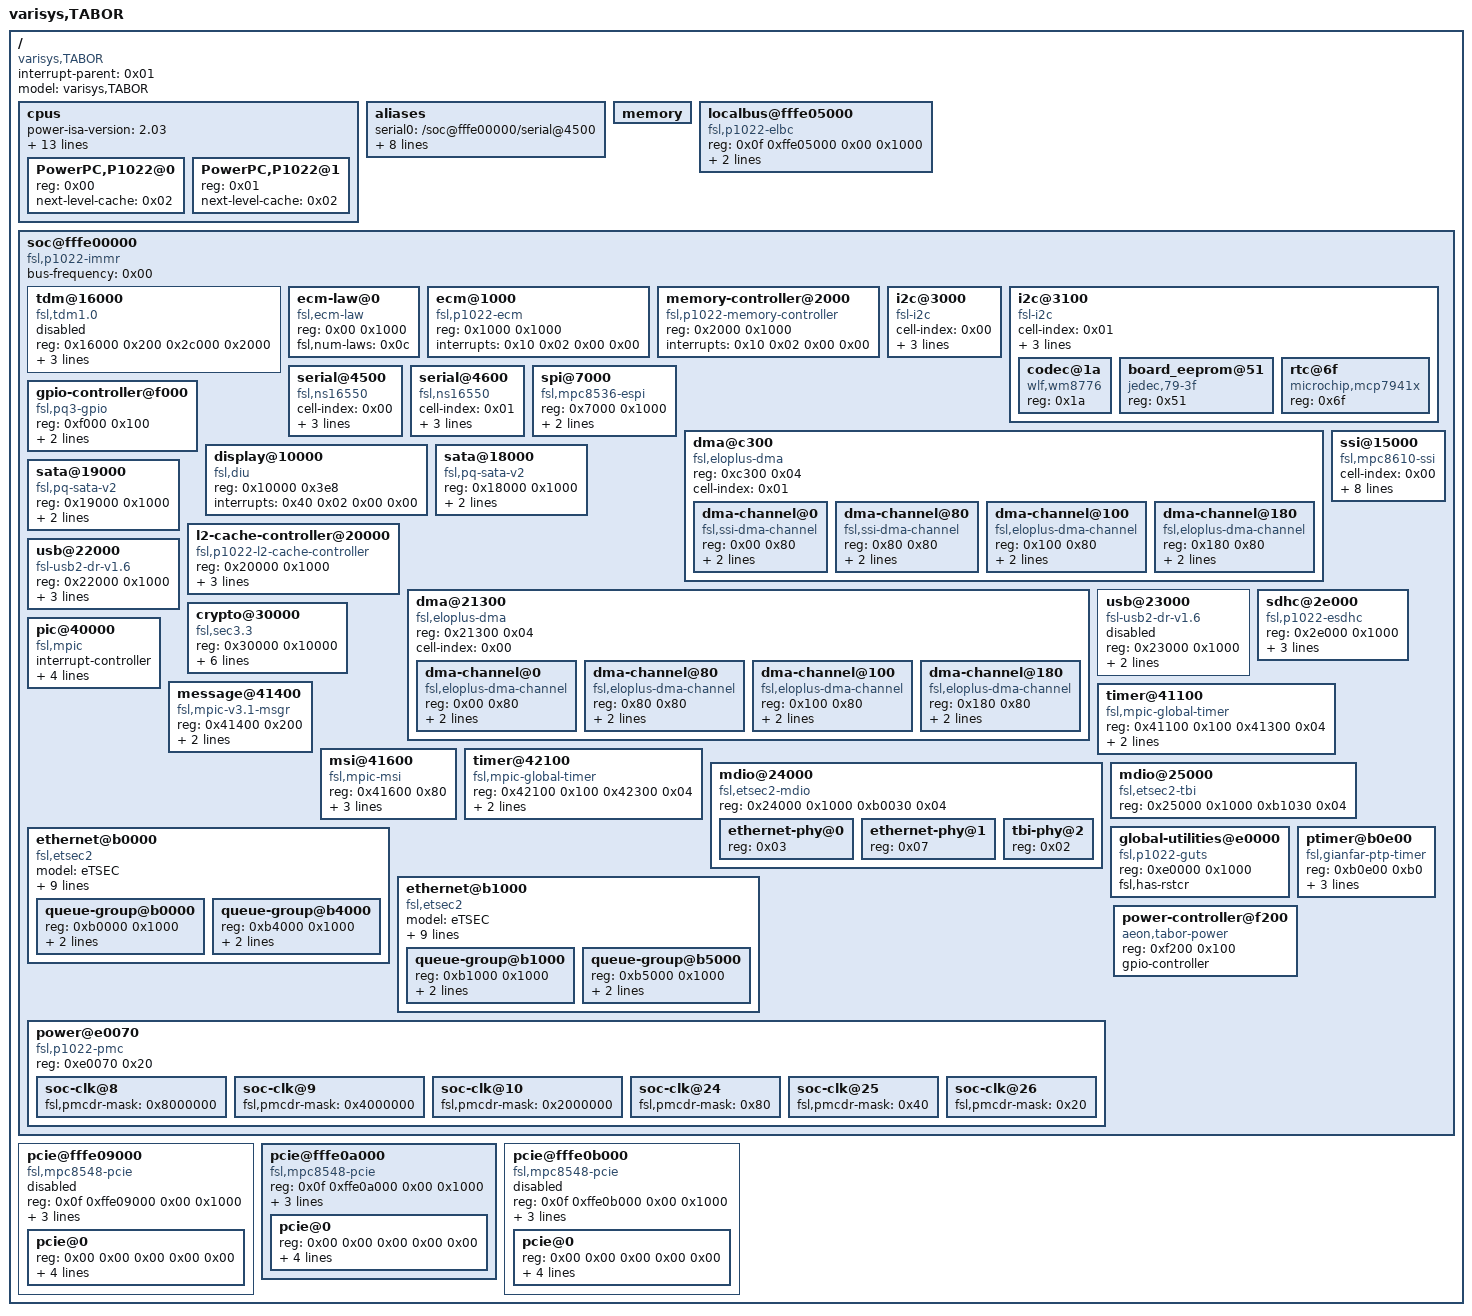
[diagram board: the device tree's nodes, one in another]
/dts-v1/;

/ {
	compatible = "varisys,TABOR";
	#address-cells = <0x02>;
	#size-cells = <0x02>;
	interrupt-parent = <0x01>;
	model = "varisys,TABOR";

	cpus {
		power-isa-version = "2.03";
		power-isa-b;
		power-isa-e;
		power-isa-atb;
		power-isa-cs;
		power-isa-e.le;
		power-isa-e.pm;
		power-isa-ecl;
		power-isa-mmc;
		power-isa-sp;
		power-isa-sp.fd;
		power-isa-sp.fs;
		power-isa-sp.fv;
		mmu-type = "power-embedded";
		#address-cells = <0x01>;
		#size-cells = <0x00>;

		PowerPC,P1022@0 {
			device_type = "cpu";
			reg = <0x00>;
			next-level-cache = <0x02>;
		};

		PowerPC,P1022@1 {
			device_type = "cpu";
			reg = <0x01>;
			next-level-cache = <0x02>;
		};
	};

	aliases {
		serial0 = "/soc@fffe00000/serial@4500";
		serial1 = "/soc@fffe00000/serial@4600";
		ethernet0 = "/soc@fffe00000/ethernet@b0000";
		ethernet1 = "/soc@fffe00000/ethernet@b1000";
		pci0 = "/pcie@fffe09000";
		pci1 = "/pcie@fffe0a000";
		pci2 = "/pcie@fffe0b000";
		vga = "/soc@fffe00000/display@10000";
		display = "/soc@fffe00000/display@10000";
	};

	memory {
		device_type = "memory";
	};

	localbus@fffe05000 {
		ranges = <0x00 0x00 0x0f 0xe8000000 0x8000000 0x01 0x00 0x0f 0xe0000000 0x8000000 0x02 0x00 0x0f 0xff800000 0x40000 0x03 0x00 0x0f 0xffdf0000 0x8000>;
		reg = <0x0f 0xffe05000 0x00 0x1000>;
		#address-cells = <0x02>;
		#size-cells = <0x01>;
		compatible = "fsl,p1022-elbc", "fsl,elbc";
		interrupts = <0x13 0x02 0x00 0x00 0x10 0x02 0x00 0x00>;
	};

	soc@fffe00000 {
		ranges = <0x00 0x0f 0xffe00000 0x100000>;
		#address-cells = <0x01>;
		#size-cells = <0x01>;
		device_type = "soc";
		compatible = "fsl,p1022-immr", "simple-bus";
		bus-frequency = <0x00>;

		tdm@16000 {
			status = "disabled";
			compatible = "fsl,tdm1.0";
			reg = <0x16000 0x200 0x2c000 0x2000>;
			clock-frequency = <0x00>;
			interrupts = <0x3e 0x08 0x00 0x00>;
			fsl,max-time-slots = <0x80>;
		};

		ecm-law@0 {
			compatible = "fsl,ecm-law";
			reg = <0x00 0x1000>;
			fsl,num-laws = <0x0c>;
		};

		ecm@1000 {
			compatible = "fsl,p1022-ecm", "fsl,ecm";
			reg = <0x1000 0x1000>;
			interrupts = <0x10 0x02 0x00 0x00>;
		};

		memory-controller@2000 {
			compatible = "fsl,p1022-memory-controller";
			reg = <0x2000 0x1000>;
			interrupts = <0x10 0x02 0x00 0x00>;
		};

		i2c@3000 {
			#address-cells = <0x01>;
			#size-cells = <0x00>;
			cell-index = <0x00>;
			compatible = "fsl-i2c";
			reg = <0x3000 0x100>;
			interrupts = <0x2b 0x02 0x00 0x00>;
			dfsrr;
		};

		i2c@3100 {
			#address-cells = <0x01>;
			#size-cells = <0x00>;
			cell-index = <0x01>;
			compatible = "fsl-i2c";
			reg = <0x3100 0x100>;
			interrupts = <0x2b 0x02 0x00 0x00>;
			dfsrr;

			codec@1a {
				compatible = "wlf,wm8776";
				reg = <0x1a>;
				linux,phandle = <0x05>;
				phandle = <0x05>;
			};

			board_eeprom@51 {
				compatible = "jedec,79-3f";
				reg = <0x51>;
			};

			rtc@6f {
				compatible = "microchip,mcp7941x";
				reg = <0x6f>;
			};
		};

		serial@4500 {
			cell-index = <0x00>;
			device_type = "serial";
			compatible = "fsl,ns16550", "ns16550";
			reg = <0x4500 0x100>;
			clock-frequency = <0x00>;
			interrupts = <0x2a 0x02 0x00 0x00>;
		};

		serial@4600 {
			cell-index = <0x01>;
			device_type = "serial";
			compatible = "fsl,ns16550", "ns16550";
			reg = <0x4600 0x100>;
			clock-frequency = <0x00>;
			interrupts = <0x2a 0x02 0x00 0x00>;
		};

		spi@7000 {
			#address-cells = <0x01>;
			#size-cells = <0x00>;
			compatible = "fsl,mpc8536-espi";
			reg = <0x7000 0x1000>;
			interrupts = <0x3b 0x02 0x00 0x00>;
			fsl,espi-num-chipselects = <0x04>;
		};

		dma@c300 {
			#address-cells = <0x01>;
			#size-cells = <0x01>;
			compatible = "fsl,eloplus-dma";
			reg = <0xc300 0x04>;
			ranges = <0x00 0xc100 0x200>;
			cell-index = <0x01>;

			dma-channel@0 {
				compatible = "fsl,ssi-dma-channel";
				reg = <0x00 0x80>;
				cell-index = <0x00>;
				interrupts = <0x4c 0x02 0x00 0x00>;
				linux,phandle = <0x03>;
				phandle = <0x03>;
			};

			dma-channel@80 {
				compatible = "fsl,ssi-dma-channel";
				reg = <0x80 0x80>;
				cell-index = <0x01>;
				interrupts = <0x4d 0x02 0x00 0x00>;
				linux,phandle = <0x04>;
				phandle = <0x04>;
			};

			dma-channel@100 {
				compatible = "fsl,eloplus-dma-channel";
				reg = <0x100 0x80>;
				cell-index = <0x02>;
				interrupts = <0x4e 0x02 0x00 0x00>;
			};

			dma-channel@180 {
				compatible = "fsl,eloplus-dma-channel";
				reg = <0x180 0x80>;
				cell-index = <0x03>;
				interrupts = <0x4f 0x02 0x00 0x00>;
			};
		};

		gpio-controller@f000 {
			#gpio-cells = <0x02>;
			compatible = "fsl,pq3-gpio";
			reg = <0xf000 0x100>;
			interrupts = <0x2f 0x02 0x00 0x00>;
			gpio-controller;
		};

		display@10000 {
			compatible = "fsl,diu", "fsl,p1022-diu";
			reg = <0x10000 0x3e8>;
			interrupts = <0x40 0x02 0x00 0x00>;
		};

		ssi@15000 {
			compatible = "fsl,mpc8610-ssi";
			cell-index = <0x00>;
			reg = <0x15000 0x100>;
			interrupts = <0x4b 0x02 0x00 0x00>;
			fsl,playback-dma = <0x03>;
			fsl,capture-dma = <0x04>;
			fsl,fifo-depth = <0x0f>;
			fsl,mode = "i2s-slave";
			codec-handle = <0x05>;
			fsl,ssi-asynchronous;
		};

		sata@18000 {
			compatible = "fsl,pq-sata-v2";
			reg = <0x18000 0x1000>;
			cell-index = <0x01>;
			interrupts = <0x4a 0x02 0x00 0x00>;
		};

		sata@19000 {
			compatible = "fsl,pq-sata-v2";
			reg = <0x19000 0x1000>;
			cell-index = <0x02>;
			interrupts = <0x29 0x02 0x00 0x00>;
		};

		l2-cache-controller@20000 {
			compatible = "fsl,p1022-l2-cache-controller";
			reg = <0x20000 0x1000>;
			cache-line-size = <0x20>;
			cache-size = <0x40000>;
			interrupts = <0x10 0x02 0x00 0x00>;
			linux,phandle = <0x02>;
			phandle = <0x02>;
		};

		dma@21300 {
			#address-cells = <0x01>;
			#size-cells = <0x01>;
			compatible = "fsl,eloplus-dma";
			reg = <0x21300 0x04>;
			ranges = <0x00 0x21100 0x200>;
			cell-index = <0x00>;

			dma-channel@0 {
				compatible = "fsl,eloplus-dma-channel";
				reg = <0x00 0x80>;
				cell-index = <0x00>;
				interrupts = <0x14 0x02 0x00 0x00>;
			};

			dma-channel@80 {
				compatible = "fsl,eloplus-dma-channel";
				reg = <0x80 0x80>;
				cell-index = <0x01>;
				interrupts = <0x15 0x02 0x00 0x00>;
			};

			dma-channel@100 {
				compatible = "fsl,eloplus-dma-channel";
				reg = <0x100 0x80>;
				cell-index = <0x02>;
				interrupts = <0x16 0x02 0x00 0x00>;
			};

			dma-channel@180 {
				compatible = "fsl,eloplus-dma-channel";
				reg = <0x180 0x80>;
				cell-index = <0x03>;
				interrupts = <0x17 0x02 0x00 0x00>;
			};
		};

		usb@22000 {
			compatible = "fsl-usb2-dr-v1.6", "fsl-usb2-dr";
			reg = <0x22000 0x1000>;
			#address-cells = <0x01>;
			#size-cells = <0x00>;
			interrupts = <0x1c 0x02 0x00 0x00>;
			fsl,pmc-handle = <0x06>;
			phy_type = "ulpi";
		};

		usb@23000 {
			compatible = "fsl-usb2-dr-v1.6", "fsl-usb2-dr";
			reg = <0x23000 0x1000>;
			#address-cells = <0x01>;
			#size-cells = <0x00>;
			interrupts = <0x2e 0x02 0x00 0x00>;
			fsl,pmc-handle = <0x07>;
			status = "disabled";
		};

		sdhc@2e000 {
			compatible = "fsl,p1022-esdhc", "fsl,esdhc";
			reg = <0x2e000 0x1000>;
			interrupts = <0x48 0x02 0x00 0x00>;
			clock-frequency = <0x00>;
			sdhci,auto-cmd12;
		};

		crypto@30000 {
			compatible = "fsl,sec3.3", "fsl,sec3.1", "fsl,sec3.0", "fsl,sec2.4", "fsl,sec2.2", "fsl,sec2.1", "fsl,sec2.0";
			reg = <0x30000 0x10000>;
			interrupts = <0x2d 0x02 0x00 0x00 0x3a 0x02 0x00 0x00>;
			fsl,num-channels = <0x04>;
			fsl,channel-fifo-len = <0x18>;
			fsl,exec-units-mask = <0x97c>;
			fsl,descriptor-types-mask = <0x3a30abf>;
		};

		pic@40000 {
			interrupt-controller;
			#address-cells = <0x00>;
			#interrupt-cells = <0x04>;
			reg = <0x40000 0x40000>;
			compatible = "fsl,mpic";
			device_type = "open-pic";
			big-endian;
			single-cpu-affinity;
			last-interrupt-source = <0xff>;
			linux,phandle = <0x01>;
			phandle = <0x01>;
		};

		timer@41100 {
			compatible = "fsl,mpic-global-timer";
			reg = <0x41100 0x100 0x41300 0x04>;
			interrupts = <0x00 0x00 0x03 0x00 0x01 0x00 0x03 0x00 0x02 0x00 0x03 0x00 0x03 0x00 0x03 0x00>;
		};

		message@41400 {
			compatible = "fsl,mpic-v3.1-msgr";
			reg = <0x41400 0x200>;
			interrupts = <0xb0 0x02 0x00 0x00 0xb1 0x02 0x00 0x00 0xb2 0x02 0x00 0x00 0xb3 0x02 0x00 0x00>;
		};

		msi@41600 {
			compatible = "fsl,mpic-msi";
			reg = <0x41600 0x80>;
			msi-available-ranges = <0x00 0x100>;
			interrupts = <0xe0 0x00 0x00 0x00 0xe1 0x00 0x00 0x00 0xe2 0x00 0x00 0x00 0xe3 0x00 0x00 0x00 0xe4 0x00 0x00 0x00 0xe5 0x00 0x00 0x00 0xe6 0x00 0x00 0x00 0xe7 0x00 0x00 0x00>;
		};

		timer@42100 {
			compatible = "fsl,mpic-global-timer";
			reg = <0x42100 0x100 0x42300 0x04>;
			interrupts = <0x04 0x00 0x03 0x00 0x05 0x00 0x03 0x00 0x06 0x00 0x03 0x00 0x07 0x00 0x03 0x00>;
		};

		mdio@24000 {
			#address-cells = <0x01>;
			#size-cells = <0x00>;
			compatible = "fsl,etsec2-mdio";
			reg = <0x24000 0x1000 0xb0030 0x04>;

			ethernet-phy@0 {
				reg = <0x03>;
				linux,phandle = <0x09>;
				phandle = <0x09>;
			};

			ethernet-phy@1 {
				reg = <0x07>;
				linux,phandle = <0x0c>;
				phandle = <0x0c>;
			};

			tbi-phy@2 {
				device_type = "tbi-phy";
				reg = <0x02>;
			};
		};

		ethernet@b0000 {
			#address-cells = <0x01>;
			#size-cells = <0x01>;
			device_type = "network";
			model = "eTSEC";
			compatible = "fsl,etsec2";
			fsl,num_rx_queues = <0x08>;
			fsl,num_tx_queues = <0x08>;
			fsl,magic-packet;
			local-mac-address = [00 00 00 00 00 00];
			fsl,wake-on-filer;
			fsl,pmc-handle = <0x08>;
			phy-handle = <0x09>;
			phy-connection-type = "rgmii-id";
			ptimer-handle = <0x0a>;
			ranges;

			queue-group@b0000 {
				#address-cells = <0x01>;
				#size-cells = <0x01>;
				reg = <0xb0000 0x1000>;
				interrupts = <0x1d 0x02 0x00 0x00 0x1e 0x02 0x00 0x00 0x22 0x02 0x00 0x00>;
			};

			queue-group@b4000 {
				#address-cells = <0x01>;
				#size-cells = <0x01>;
				reg = <0xb4000 0x1000>;
				interrupts = <0x11 0x02 0x00 0x00 0x12 0x02 0x00 0x00 0x18 0x02 0x00 0x00>;
			};
		};

		mdio@25000 {
			#address-cells = <0x01>;
			#size-cells = <0x00>;
			compatible = "fsl,etsec2-tbi";
			reg = <0x25000 0x1000 0xb1030 0x04>;
		};

		ethernet@b1000 {
			#address-cells = <0x01>;
			#size-cells = <0x01>;
			device_type = "network";
			model = "eTSEC";
			compatible = "fsl,etsec2";
			fsl,num_rx_queues = <0x08>;
			fsl,num_tx_queues = <0x08>;
			fsl,magic-packet;
			local-mac-address = [00 00 00 00 00 00];
			fsl,wake-on-filer;
			fsl,pmc-handle = <0x0b>;
			phy-handle = <0x0c>;
			phy-connection-type = "rgmii-id";
			ptimer-handle = <0x0a>;
			ranges;

			queue-group@b1000 {
				#address-cells = <0x01>;
				#size-cells = <0x01>;
				reg = <0xb1000 0x1000>;
				interrupts = <0x23 0x02 0x00 0x00 0x24 0x02 0x00 0x00 0x28 0x02 0x00 0x00>;
			};

			queue-group@b5000 {
				#address-cells = <0x01>;
				#size-cells = <0x01>;
				reg = <0xb5000 0x1000>;
				interrupts = <0x33 0x02 0x00 0x00 0x34 0x02 0x00 0x00 0x43 0x02 0x00 0x00>;
			};
		};

		global-utilities@e0000 {
			compatible = "fsl,p1022-guts";
			reg = <0xe0000 0x1000>;
			fsl,has-rstcr;
		};

		power@e0070 {
			compatible = "fsl,p1022-pmc", "fsl,mpc8536-pmc", "fsl,mpc8548-pmc";
			reg = <0xe0070 0x20>;

			soc-clk@8 {
				fsl,pmcdr-mask = <0x8000000>;
				linux,phandle = <0x06>;
				phandle = <0x06>;
			};

			soc-clk@9 {
				fsl,pmcdr-mask = <0x4000000>;
				linux,phandle = <0x07>;
				phandle = <0x07>;
			};

			soc-clk@10 {
				fsl,pmcdr-mask = <0x2000000>;
			};

			soc-clk@24 {
				fsl,pmcdr-mask = <0x80>;
				linux,phandle = <0x08>;
				phandle = <0x08>;
			};

			soc-clk@25 {
				fsl,pmcdr-mask = <0x40>;
				linux,phandle = <0x0b>;
				phandle = <0x0b>;
			};

			soc-clk@26 {
				fsl,pmcdr-mask = <0x20>;
			};
		};

		ptimer@b0e00 {
			compatible = "fsl,gianfar-ptp-timer";
			reg = <0xb0e00 0xb0>;
			fsl,ts-to-buffer;
			fsl,tmr-prsc = <0x02>;
			fsl,clock-source-select = <0x01>;
			linux,phandle = <0x0a>;
			phandle = <0x0a>;
		};

		power-controller@f200 {
			#gpio-cells = <0x02>;
			compatible = "aeon,tabor-power";
			reg = <0xf200 0x100>;
			gpio-controller;
		};
	};

	pcie@fffe09000 {
		ranges = <0x2000000 0x00 0xe0000000 0x0c 0x20000000 0x00 0x20000000 0x1000000 0x00 0x00 0x0f 0xffc10000 0x00 0x10000>;
		reg = <0x0f 0xffe09000 0x00 0x1000>;
		status = "disabled";
		compatible = "fsl,mpc8548-pcie";
		device_type = "pci";
		#size-cells = <0x02>;
		#address-cells = <0x03>;
		bus-range = <0x00 0xff>;
		clock-frequency = <0x1fca055>;
		interrupts = <0x10 0x02 0x00 0x00>;

		pcie@0 {
			ranges = <0x2000000 0x00 0xe0000000 0x2000000 0x00 0xe0000000 0x00 0x20000000 0x1000000 0x00 0x00 0x1000000 0x00 0x00 0x00 0x100000>;
			reg = <0x00 0x00 0x00 0x00 0x00>;
			#interrupt-cells = <0x01>;
			#size-cells = <0x02>;
			#address-cells = <0x03>;
			device_type = "pci";
			interrupts = <0x10 0x02 0x00 0x00>;
			interrupt-map-mask = <0xf800 0x00 0x00 0x07>;
			interrupt-map = <0x00 0x00 0x00 0x01 0x01 0x04 0x01 0x00 0x00 0x00 0x00 0x00 0x02 0x01 0x05 0x01 0x00 0x00 0x00 0x00 0x00 0x03 0x01 0x06 0x01 0x00 0x00 0x00 0x00 0x00 0x04 0x01 0x07 0x01 0x00 0x00>;
		};
	};

	pcie@fffe0a000 {
		ranges = <0x2000000 0x00 0xe0000000 0x0c 0x40000000 0x00 0x20000000 0x1000000 0x00 0x00 0x0f 0xffc20000 0x00 0x10000>;
		reg = <0x0f 0xffe0a000 0x00 0x1000>;
		compatible = "fsl,mpc8548-pcie";
		device_type = "pci";
		#size-cells = <0x02>;
		#address-cells = <0x03>;
		bus-range = <0x00 0xff>;
		clock-frequency = <0x1fca055>;
		interrupts = <0x10 0x02 0x00 0x00>;

		pcie@0 {
			ranges = <0x2000000 0x00 0xe0000000 0x2000000 0x00 0xe0000000 0x00 0x20000000 0x1000000 0x00 0x00 0x1000000 0x00 0x00 0x00 0x100000>;
			reg = <0x00 0x00 0x00 0x00 0x00>;
			#interrupt-cells = <0x01>;
			#size-cells = <0x02>;
			#address-cells = <0x03>;
			device_type = "pci";
			interrupts = <0x10 0x02 0x00 0x00>;
			interrupt-map-mask = <0xf800 0x00 0x00 0x07>;
			interrupt-map = <0x00 0x00 0x00 0x01 0x01 0x00 0x01 0x00 0x00 0x00 0x00 0x00 0x02 0x01 0x01 0x01 0x00 0x00 0x00 0x00 0x00 0x03 0x01 0x02 0x01 0x00 0x00 0x00 0x00 0x00 0x04 0x01 0x03 0x01 0x00 0x00>;
		};
	};

	pcie@fffe0b000 {
		ranges = <0x2000000 0x00 0xe0000000 0x0c 0x00 0x00 0x20000000 0x1000000 0x00 0x00 0x0f 0xffc00000 0x00 0x10000>;
		reg = <0x0f 0xffe0b000 0x00 0x1000>;
		status = "disabled";
		compatible = "fsl,mpc8548-pcie";
		device_type = "pci";
		#size-cells = <0x02>;
		#address-cells = <0x03>;
		bus-range = <0x00 0xff>;
		clock-frequency = <0x1fca055>;
		interrupts = <0x10 0x02 0x00 0x00>;

		pcie@0 {
			ranges = <0x2000000 0x00 0xe0000000 0x2000000 0x00 0xe0000000 0x00 0x20000000 0x1000000 0x00 0x00 0x1000000 0x00 0x00 0x00 0x100000>;
			reg = <0x00 0x00 0x00 0x00 0x00>;
			#interrupt-cells = <0x01>;
			#size-cells = <0x02>;
			#address-cells = <0x03>;
			device_type = "pci";
			interrupts = <0x10 0x02 0x00 0x00>;
			interrupt-map-mask = <0xf800 0x00 0x00 0x07>;
			interrupt-map = <0x00 0x00 0x00 0x01 0x01 0x08 0x01 0x00 0x00 0x00 0x00 0x00 0x02 0x01 0x09 0x01 0x00 0x00 0x00 0x00 0x00 0x03 0x01 0x0a 0x01 0x00 0x00 0x00 0x00 0x00 0x04 0x01 0x0b 0x01 0x00 0x00>;
		};
	};
};
